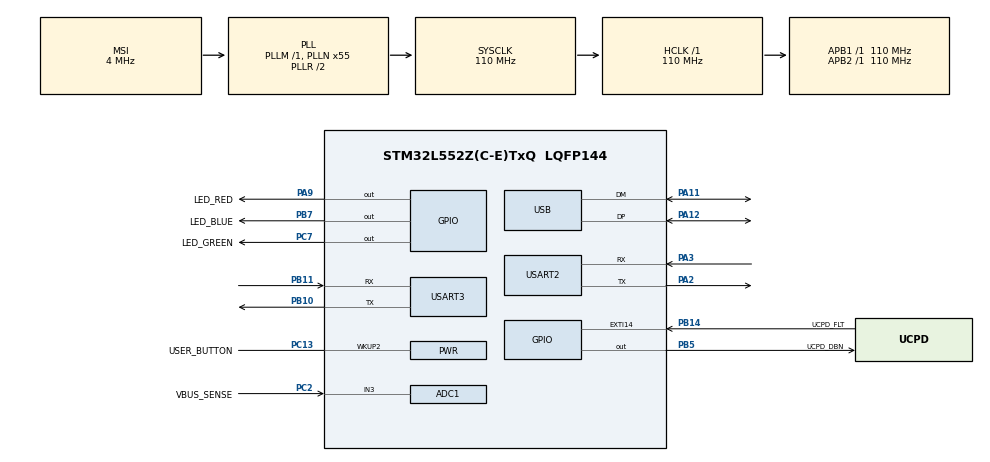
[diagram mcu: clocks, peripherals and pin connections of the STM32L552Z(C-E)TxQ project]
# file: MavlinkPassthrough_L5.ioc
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ADC1.Channel-0\#ChannelRegularConversion=ADC_CHANNEL_3
ADC1.NbrOfConversionFlag=1
ADC1.OffsetNumber-0\#ChannelRegularConversion=ADC_OFFSET_NONE
ADC1.Rank-0\#ChannelRegularConversion=1
ADC1.SamplingTime-0\#ChannelRegularConversion=ADC_SAMPLETIME_2CYCLES_5
ADC1.master=1
Dma.Request0=USART2_RX
Dma.Request1=USART3_RX
Dma.USART2_RX.0.Channel_PRIV_NPRIV=DMA_CHANNEL_NPRIV_DISABLE
Dma.USART2_RX.0.Direction=DMA_PERIPH_TO_MEMORY
Dma.USART2_RX.0.EventEnable=DISABLE
Dma.USART2_RX.0.Instance=DMA1_Channel2
Dma.USART2_RX.0.MemDataAlignment=DMA_MDATAALIGN_BYTE
Dma.USART2_RX.0.MemInc=DMA_MINC_ENABLE
Dma.USART2_RX.0.Mode=DMA_NORMAL
Dma.USART2_RX.0.PeriphDataAlignment=DMA_PDATAALIGN_BYTE
Dma.USART2_RX.0.PeriphInc=DMA_PINC_DISABLE
Dma.USART2_RX.0.Polarity=HAL_DMAMUX_REQ_GEN_RISING
Dma.USART2_RX.0.Priority=DMA_PRIORITY_LOW
Dma.USART2_RX.0.RequestNumber=1
Dma.USART2_RX.0.SignalID=NONE
Dma.USART2_RX.0.SyncEnable=DISABLE
Dma.USART2_RX.0.SyncPolarity=HAL_DMAMUX_SYNC_NO_EVENT
Dma.USART2_RX.0.SyncRequestNumber=1
Dma.USART2_RX.0.SyncSignalID=NONE
Dma.USART3_RX.1.Channel_PRIV_NPRIV=DMA_CHANNEL_NPRIV_DISABLE
Dma.USART3_RX.1.Direction=DMA_PERIPH_TO_MEMORY
Dma.USART3_RX.1.EventEnable=DISABLE
Dma.USART3_RX.1.Instance=DMA1_Channel1
Dma.USART3_RX.1.MemDataAlignment=DMA_MDATAALIGN_BYTE
Dma.USART3_RX.1.MemInc=DMA_MINC_ENABLE
Dma.USART3_RX.1.Mode=DMA_NORMAL
Dma.USART3_RX.1.PeriphDataAlignment=DMA_PDATAALIGN_BYTE
Dma.USART3_RX.1.PeriphInc=DMA_PINC_DISABLE
Dma.USART3_RX.1.Polarity=HAL_DMAMUX_REQ_GEN_RISING
Dma.USART3_RX.1.Priority=DMA_PRIORITY_LOW
Dma.USART3_RX.1.RequestNumber=1
Dma.USART3_RX.1.SignalID=NONE
Dma.USART3_RX.1.SyncEnable=DISABLE
Dma.USART3_RX.1.SyncPolarity=HAL_DMAMUX_SYNC_NO_EVENT
Dma.USART3_RX.1.SyncRequestNumber=1
Dma.USART3_RX.1.SyncSignalID=NONE
Mcu.Family=STM32L5
Mcu.Name=STM32L552Z(C-E)TxQ
Mcu.Package=LQFP144
Mcu.TrustZone=disable
NVIC.DMA1_Channel1_IRQn=true\:0\:0\:false\:false\:true\:false\:true\:true
NVIC.DMA1_Channel2_IRQn=true\:0\:0\:false\:false\:true\:false\:true\:true
NVIC.PriorityGroup=NVIC_PRIORITYGROUP_3
NVIC.USART2_IRQn=true\:0\:0\:false\:false\:true\:true\:true\:true
NVIC.USART3_IRQn=true\:0\:0\:false\:false\:true\:true\:true\:true
PA11.Mode=Device
PA11.Signal=USB_DM
PA12.Mode=Device
PA12.Signal=USB_DP
PA13\ (JTMS/SWDIO).Mode=Trace_Asynchronous_SW
PA13\ (JTMS/SWDIO).Signal=DEBUG_JTMS-SWDIO
PA14\ (JTCK/SWCLK).Mode=Trace_Asynchronous_SW
PA14\ (JTCK/SWCLK).Signal=DEBUG_JTCK-SWCLK
PA15\ (JTDI).Signal=UCPD1_CC1
PA2.Mode=Asynchronous
PA2.Signal=USART2_TX
PA3.Mode=Asynchronous
PA3.Signal=USART2_RX
PA9.GPIO_Label=LED_RED
PA9.Signal=GPIO_Output
PB10.Mode=Asynchronous
PB10.Signal=USART3_TX
PB11.Mode=Asynchronous
PB11.Signal=USART3_RX
PB14.GPIO_Label=UCPD_FLT
PB14.Signal=GPXTI14
PB15.Signal=UCPD1_CC2
PB3\ (JTDO/TRACESWO).Mode=Trace_Asynchronous_SW
PB3\ (JTDO/TRACESWO).Signal=DEBUG_JTDO-SWO
PB5.GPIO_Label=UCPD_DBN
PB5.Signal=GPIO_Output
PB7.GPIO_Label=LED_BLUE
PB7.Signal=GPIO_Output
PC13.GPIO_Label=USER_BUTTON
PC13.Mode=WakeUp1
PC13.Signal=PWR_WKUP2
PC14-OSC32_IN\ (PC14).Mode=LSE-External-Oscillator
PC14-OSC32_IN\ (PC14).Signal=RCC_OSC32_IN
PC15-OSC32_OUT\ (PC15).Mode=LSE-External-Oscillator
PC15-OSC32_OUT\ (PC15).Signal=RCC_OSC32_OUT
PC2.GPIO_Label=VBUS_SENSE
PC2.Signal=ADCx_IN3
PC7.GPIO_Label=LED_GREEN
PC7.Signal=GPIO_Output
PG7.GPIO_Label=ST-LINK_VCP_TX
PG7.Signal=LPUART1_TX
PG8.GPIO_Label=ST-LINK_VCP_RX
PG8.Signal=LPUART1_RX
ProjectManager.HeapSize=0x200
ProjectManager.StackSize=0x400
ProjectManager.TargetToolchain=STM32CubeIDE
RCC.ADCCLockSelection=RCC_ADCCLKSOURCE_SYSCLK
RCC.ADCFreq_Value=110000000
RCC.AHBFreq_Value=110000000
RCC.APB1Freq_Value=110000000
RCC.APB1TimFreq_Value=110000000
RCC.APB2Freq_Value=110000000
RCC.APB2TimFreq_Value=110000000
RCC.CK48CLockSelection=RCC_USBCLKSOURCE_HSI48
RCC.CortexFreq_Value=110000000
RCC.HCLKFreq_Value=110000000
RCC.HSE_VALUE=8000000
RCC.HSI48_VALUE=48000000
RCC.HSI_VALUE=16000000
RCC.MSI_VALUE=4000000
RCC.PLLN=55
RCC.PLLSAI1N=24
RCC.RTCClockSelection=RCC_RTCCLKSOURCE_LSE
RCC.SYSCLKFreq_VALUE=110000000
RCC.SYSCLKSource=RCC_SYSCLKSOURCE_PLLCLK
RCC.USBFreq_Value=48000000
RCC.VCOOutputFreq_Value=220000000
SH.ADCx_IN3.0=ADC1_IN3,IN3-Single-Ended
USART2.VirtualMode-Asynchronous=VM_ASYNC
USART3.VirtualMode-Asynchronous=VM_ASYNC
VP_PWR_VS_DBSignals.Mode=DisableDeadBatterySignals
VP_RTC_VS_RTC_Activate.Mode=RTC_Enabled
board=NUCLEO-L552ZE-Q

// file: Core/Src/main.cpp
/* USER CODE BEGIN Header */
/**
  ******************************************************************************
  * @file           : main.c
  * @brief          : Main program body
  ******************************************************************************
  * @attention
  *
  * Copyright (c) 2023 STMicroelectronics.
  * All rights reserved.
  *
  * This software is licensed under terms that can be found in the LICENSE file
  * in the root directory of this software component.
  * If no LICENSE file comes with this software, it is provided AS-IS.
  *
  ******************************************************************************
  */
/* USER CODE END Header */
#include "main.h"
#include "adc.h"
#include "dma.h"
#include "rtc.h"
#include "usart.h"
#include "usb.h"
#include "gpio.h"
#include "CommonDataTypes.hpp"

void SystemClock_Config(void);

int main(void)
{

  /* MCU Configuration--------------------------------------------------------*/

  /* Reset of all peripherals, Initializes the Flash interface and the Systick. */
  HAL_Init();

  /* Configure the system clock */
  SystemClock_Config();

  /* Initialize all configured peripherals */
  MX_GPIO_Init();
  MX_DMA_Init();
  MX_RTC_Init();
  MX_USB_PCD_Init();
  MX_USART3_UART_Init();
  MX_USART2_UART_Init();
  MX_ADC1_Init();

  /* Infinite loop */
  while (1)
  {

    /* USER CODE BEGIN 3 */
	  mavlink_message_t upstreamMessage;
	  bool upmessageRead = drone_mavlink->readMessage(upstreamMessage);
	  if(upmessageRead){
	  	  antenna_mavlink->writeMessage(upstreamMessage);
	  }

	  mavlink_message_t downstreamMessage;
	  bool downmessageRead = antenna_mavlink->readMessage(downstreamMessage);
	  if(downmessageRead){
		  drone_mavlink->writeMessage(downstreamMessage);
	  }
  }
  /* USER CODE END 3 */
}

void SystemClock_Config(void)
{
  RCC_OscInitTypeDef RCC_OscInitStruct = {0};
  RCC_ClkInitTypeDef RCC_ClkInitStruct = {0};

  /** Configure the main internal regulator output voltage
  */
  if (HAL_PWREx_ControlVoltageScaling(PWR_REGULATOR_VOLTAGE_SCALE0) != HAL_OK)
  {
    Error_Handler();
  }

  /** Configure LSE Drive Capability
  */
  HAL_PWR_EnableBkUpAccess();
  __HAL_RCC_LSEDRIVE_CONFIG(RCC_LSEDRIVE_LOW);

  /** Initializes the RCC Oscillators according to the specified parameters
  * in the RCC_OscInitTypeDef structure.
  */
  RCC_OscInitStruct.OscillatorType = RCC_OSCILLATORTYPE_HSI48|RCC_OSCILLATORTYPE_LSE
                              |RCC_OSCILLATORTYPE_MSI;
  RCC_OscInitStruct.LSEState = RCC_LSE_ON;
  RCC_OscInitStruct.HSI48State = RCC_HSI48_ON;
  RCC_OscInitStruct.MSIState = RCC_MSI_ON;
  RCC_OscInitStruct.MSICalibrationValue = RCC_MSICALIBRATION_DEFAULT;
  RCC_OscInitStruct.MSIClockRange = RCC_MSIRANGE_6;
  RCC_OscInitStruct.PLL.PLLState = RCC_PLL_ON;
  RCC_OscInitStruct.PLL.PLLSource = RCC_PLLSOURCE_MSI;
  RCC_OscInitStruct.PLL.PLLM = 1;
  RCC_OscInitStruct.PLL.PLLN = 55;
  RCC_OscInitStruct.PLL.PLLP = RCC_PLLP_DIV7;
  RCC_OscInitStruct.PLL.PLLQ = RCC_PLLQ_DIV2;
  RCC_OscInitStruct.PLL.PLLR = RCC_PLLR_DIV2;
  if (HAL_RCC_OscConfig(&RCC_OscInitStruct) != HAL_OK)
  {
    Error_Handler();
  }

  /** Initializes the CPU, AHB and APB buses clocks
  */
  RCC_ClkInitStruct.ClockType = RCC_CLOCKTYPE_HCLK|RCC_CLOCKTYPE_SYSCLK
                              |RCC_CLOCKTYPE_PCLK1|RCC_CLOCKTYPE_PCLK2;
  RCC_ClkInitStruct.SYSCLKSource = RCC_SYSCLKSOURCE_PLLCLK;
  RCC_ClkInitStruct.AHBCLKDivider = RCC_SYSCLK_DIV1;
  RCC_ClkInitStruct.APB1CLKDivider = RCC_HCLK_DIV1;
  RCC_ClkInitStruct.APB2CLKDivider = RCC_HCLK_DIV1;

  if (HAL_RCC_ClockConfig(&RCC_ClkInitStruct, FLASH_LATENCY_5) != HAL_OK)
  {
    Error_Handler();
  }
}

void Error_Handler(void)
{
  __disable_irq();
  while (1)
  {
  }
}
